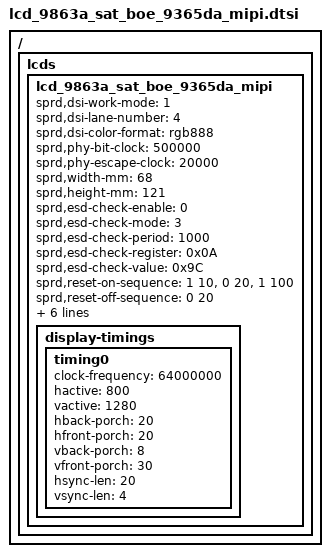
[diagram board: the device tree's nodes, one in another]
/ { lcds {
	lcd_9863a_sat_boe_9365da_mipi: lcd_9863a_sat_boe_9365da_mipi {

		sprd,dsi-work-mode = <1>;
		sprd,dsi-lane-number = <4>;
		sprd,dsi-color-format = "rgb888";

		sprd,phy-bit-clock = <500000>;
		sprd,phy-escape-clock = <20000>;

		sprd,width-mm = <68>;
		sprd,height-mm = <121>;

		sprd,esd-check-enable = <0>;
		sprd,esd-check-mode = <3>;
		sprd,esd-check-period = <1000>;
		sprd,esd-check-register = <0x0A>;
		sprd,esd-check-value = <0x9C>;

		sprd,reset-on-sequence = <1 10>, <0 20>, <1 100>;
		sprd,reset-off-sequence = <0 20>;

		sprd,initial-command = [
			23 00 00 02 E0 00 

			23 00 00 02 E1 93 
			23 00 00 02 E2 65 
			23 00 00 02 E3 F8 
			23 00 00 02 80 03 



			23 00 00 02 E0 01 

			23 00 00 02 00 00 
			23 00 00 02 01 26 


			23 00 00 02 17 00 
			23 00 00 02 18 D7 //4.8V
			23 00 00 02 19 01 //0.3V
			23 00 00 02 1A 00 
			23 00 00 02 1B D7   //VGMN=0
			23 00 00 02 1C 01 

			23 00 00 02 1F 70 	//VGH_REG=16.2V
			23 00 00 02 20 2D 	//VGL_REG=-12V
			23 00 00 02 21 2D 	//VGL_REG2=-12V
			23 00 00 02 22 7E 
			23 00 00 02 24 FD 

			23 00 00 02 37 19 	//SS=1 BGR=1

			23 00 00 02 35 28 	//SAP

			23 00 00 02 38 05 	//JDT=101 zigzag inversion
			23 00 00 02 39 08 
			23 00 00 02 3A 12 
			23 00 00 02 3C 7E 	//SET EQ3 for TE_H
			23 00 00 02 3D FF 	//SET CHGEN_ON  modify 20140806
			23 00 00 02 3E FF 	//SET CHGEN_OFF  modify 20140806
			23 00 00 02 3F 7F 	//SET CHGEN_OFF2  modify 20140806


			23 00 00 02 40 06 	//RSO=
			23 00 00 02 41 A0 	//LN=640->1280 line
			23 00 00 02 43 1E 	//VFP=
			23 00 00 02 44 0B 	//VBP



			23 00 00 02 55 01 	//DCDCM=1111
			23 00 00 02 56 01 
			23 00 00 02 57 6A 
			23 00 00 02 58 09 
			23 00 00 02 59 0A 	//VCL = -2.5V
			23 00 00 02 5A 2E 	//VGH = 16.2V
			23 00 00 02 5B 1A 	//VGL = -12V
			23 00 00 02 5C 15 	//pump clk



			23 00 00 02 5D 7F 
			23 00 00 02 5E 5D 
			23 00 00 02 5F 4B 
			23 00 00 02 60 3E 
			23 00 00 02 61 3A 
			23 00 00 02 62 2B 
			23 00 00 02 63 2F 
			23 00 00 02 64 19 
			23 00 00 02 65 32 
			23 00 00 02 66 31 
			23 00 00 02 67 31 
			23 00 00 02 68 4F 
			23 00 00 02 69 3E 
			23 00 00 02 6A 47 
			23 00 00 02 6B 36 
			23 00 00 02 6C 31 
			23 00 00 02 6D 24 
			23 00 00 02 6E 12 
			23 00 00 02 6F 02 
			23 00 00 02 70 7F 
			23 00 00 02 71 5D 
			23 00 00 02 72 4B 
			23 00 00 02 73 3E 
			23 00 00 02 74 3A 
			23 00 00 02 75 2B 
			23 00 00 02 76 2F 
			23 00 00 02 77 19 
			23 00 00 02 78 32 
			23 00 00 02 79 31 
			23 00 00 02 7A 31 
			23 00 00 02 7B 4F 
			23 00 00 02 7C 3E 
			23 00 00 02 7D 47 
			23 00 00 02 7E 36 
			23 00 00 02 7F 31 
			23 00 00 02 80 24 
			23 00 00 02 81 12 
			23 00 00 02 82 02 

			23 00 00 02 E0 02 

			23 00 00 02 00 52 //RESET_EVEN
			23 00 00 02 01 55 //VSSG_EVEN
			23 00 00 02 02 55 //VSSG_EVEN
			23 00 00 02 03 50 //STV2_ODD
			23 00 00 02 04 77 //VDD2_ODD
			23 00 00 02 05 57 //VDD1_ODD
			23 00 00 02 06 55 //x
			23 00 00 02 07 4E //CK11
			23 00 00 02 08 4C //CK9
			23 00 00 02 09 5F //x
			23 00 00 02 0A 4A //CK7
			23 00 00 02 0B 48 //CK5
			23 00 00 02 0C 55 //x
			23 00 00 02 0D 46 //CK3
			23 00 00 02 0E 44 //CK1
			23 00 00 02 0F 40 //STV1_ODD
			23 00 00 02 10 55 //x
			23 00 00 02 11 55 //x
			23 00 00 02 12 55 //x
			23 00 00 02 13 55 //x
			23 00 00 02 14 55 //x
			23 00 00 02 15 55 //x

			23 00 00 02 16 53 //RESET__EVEN
			23 00 00 02 17 55 //VSSG_EVEN
			23 00 00 02 18 55 //VSSG_EVEN
			23 00 00 02 19 51 //STV2_EVEN
			23 00 00 02 1A 77 //VDD2_EVEN
			23 00 00 02 1B 57 //VDD1_EVEN
			23 00 00 02 1C 55 //x
			23 00 00 02 1D 4F //CK12
			23 00 00 02 1E 4D //CK10
			23 00 00 02 1F 5F //x
			23 00 00 02 20 4B //CK8
			23 00 00 02 21 49 //CK6
			23 00 00 02 22 55 //x
			23 00 00 02 23 47 //CK4
			23 00 00 02 24 45 //CK2
			23 00 00 02 25 41 //STV1_EVEN
			23 00 00 02 26 55 //x
			23 00 00 02 27 55 //x
			23 00 00 02 28 55 //x
			23 00 00 02 29 55 //x
			23 00 00 02 2A 55 //x
			23 00 00 02 2B 55 //x

			23 00 00 02 2C 13 //RESET_EVEN
			23 00 00 02 2D 15 //VSSG_EVEN
			23 00 00 02 2E 15 //VSSG_EVEN
			23 00 00 02 2F 01 //STV2_ODD
			23 00 00 02 30 37 //VDD2_ODD
			23 00 00 02 31 17 //VDD1_ODD
			23 00 00 02 32 15 //x
			23 00 00 02 33 0D //CK11
			23 00 00 02 34 0F //CK9
			23 00 00 02 35 15 //x
			23 00 00 02 36 05 //CK7
			23 00 00 02 37 07 //CK5
			23 00 00 02 38 15 //x
			23 00 00 02 39 09 //CK3
			23 00 00 02 3A 0B //CK1
			23 00 00 02 3B 11 //STV1_ODD
			23 00 00 02 3C 15 //x
			23 00 00 02 3D 15 //x
			23 00 00 02 3E 15 //x
			23 00 00 02 3F 15 //x
			23 00 00 02 40 15 //x
			23 00 00 02 41 15 //x

			23 00 00 02 42 12 //RESET__EVEN
			23 00 00 02 43 15 //VSSG_EVEN
			23 00 00 02 44 15 //VSSG_EVEN
			23 00 00 02 45 00 //STV2_EVEN
			23 00 00 02 46 37 //VDD2_EVEN
			23 00 00 02 47 17 //VDD1_EVEN
			23 00 00 02 48 15 //x
			23 00 00 02 49 0C //CK12
			23 00 00 02 4A 0E //CK10
			23 00 00 02 4B 15 //x
			23 00 00 02 4C 04 //CK8
			23 00 00 02 4D 06 //CK6
			23 00 00 02 4E 15 //x
			23 00 00 02 4F 08 //CK4
			23 00 00 02 50 0A //CK2
			23 00 00 02 51 10 //STV1_EVEN
			23 00 00 02 52 15 //x
			23 00 00 02 53 15 //x
			23 00 00 02 54 15 //x
			23 00 00 02 55 15 //x
			23 00 00 02 56 15 //x
			23 00 00 02 57 15 //x

			23 00 00 02 58 40 
			23 00 00 02 5B 10 
			23 00 00 02 5C 06 //STV_S0
			23 00 00 02 5D 40 
			23 00 00 02 5E 00 
			23 00 00 02 5F 00 
			23 00 00 02 60 40 //ETV_W
			23 00 00 02 61 03 
			23 00 00 02 62 04 
			23 00 00 02 63 6C //CKV_ON
			23 00 00 02 64 6C //CKV_OFF
			23 00 00 02 65 75 
			23 00 00 02 66 08 //ETV_S0
			23 00 00 02 67 B4  //ckv_num/ckv_w
			23 00 00 02 68 08  //CKV_S0
			23 00 00 02 69 6C //CKV_ON
			23 00 00 02 6A 6C //CKV_OFF
			23 00 00 02 6B 0C  //dummy
			23 00 00 02 6D 00 //GGND1
			23 00 00 02 6E 00 //GGND2
			23 00 00 02 6F 88 
			23 00 00 02 75 BB //FLM_EN
			23 00 00 02 76 00 
			23 00 00 02 77 05 
			23 00 00 02 78 2A //FLM_OFF

			23 00 00 02 E0 04 
			23 00 00 02 09 11 
			23 00 00 02 0E 48 	//Source EQ option
			23 00 00 02 2D 03 //defult 0x01



			23 00 00 02 E0 00 
			23 00 00 02 E6 02 //WD_Timer
			23 00 00 02 E7 06 //WD_Timer
			13 78 00 01 11
			13 64 00 01 29
			];
		sprd,sleep-in-command = [
			13 0A 00 01 28
			13 78 00 01 10
			];
		sprd,sleep-out-command = [
			13 78 00 01 11
			13 64 00 01 29
			];

		display-timings {
			timing0 {
			clock-frequency = <64000000>;
			hactive = <800>;
			vactive = <1280>;
			hback-porch = <20>;
			hfront-porch = <20>;
			vback-porch = <8>;
			vfront-porch = <30>;
			hsync-len = <20>;
			vsync-len = <4>;
			};
		};
	};
};};

